# max32572 register map
Vendor: Maxim-Integrated; Series: ARMCM4; File version: 1.0
CPU: CM4 r2p1, little endian, MPU, FPU, 3 interrupt priority bits
Registers are 32-bit, read-write, reset 0x0 unless marked. A register's access mark holds for its fields unless they carry their own. Offsets are from the block's base; [hi:lo] are bit positions.

## RTC — Real Time Clock and Alarm.
Base 0x40006000
0x00 SEC reset not defined — RTC Second Counter. This register contains the 32-bit second counter.
  [31:0] SEC — Seconds Counter.
0x04 SSEC reset not defined — RTC Sub-second Counter. This counter increments at 256Hz. RTC_SEC is incremented when this register rolls over from 0xFF to 0x00.
  [11:0] SSEC — Sub-Seconds Counter (12-bit).
0x08 TODA reset not defined — Time-of-day Alarm.
  [19:0] TOD_ALARM
0x0C SSECA reset not defined — RTC sub-second alarm. This register contains the reload value for the sub-second alarm.
  [31:0] SSEC_ALARM — This register contains the reload value for the sub-second alarm.
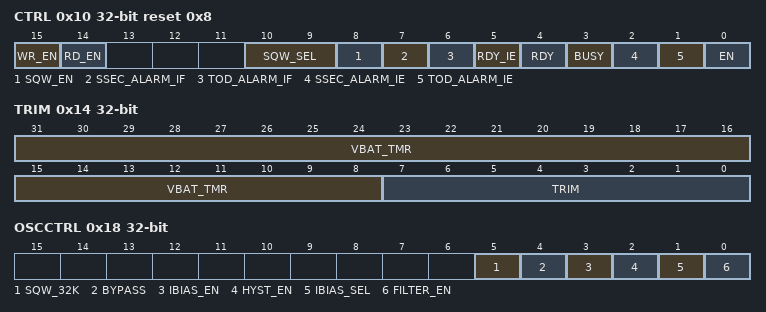
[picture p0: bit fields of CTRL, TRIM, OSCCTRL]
0x10 CTRL reset 0x8 (reset mask 0xFFFFFF38) — RTC Control Register.
  [15] WR_EN — Write Enable. This register bit serves as a protection mechanism against unintentional writes to critical RTC bits.
    0=Ignored; 1=Allowed
  [14] RD_EN — Asynchronous Counter Read Enable.
    0=Synchronous; 1=Asynchronous
  [10:9] SQW_SEL — Frequency Output Selection. When SQE=1, these bits specify the output frequency on the SQW pin.
    0=freq1Hz (1 Hz (Compensated).); 1=freq512Hz (512 Hz (Compensated).); 2=freq4KHz (4 KHz.); 3=clkDiv8 (RTC Input Clock / 8.)
  [8] SQW_EN — Square Wave Output Enable.
    0=dis (Disable.); 1=en (Enable.)
  [7] SSEC_ALARM_IF ro — Sub-second Alarm Interrupt Flag. This alarm is qualified as wake-up source to the processor.
    0=inactive (Not active.); 1=pending (Active.)
  [6] TOD_ALARM_IF ro — Time-of-Day Alarm Interrupt Flag. This alarm is qualified as wake-up source to the processor.
    0=inactive (Not active.); 1=pending (Active.)
  [5] RDY_IE — RTC Ready Interrupt Enable.
    0=dis (Disable.); 1=en (Enable.)
  [4] RDY — RTC Ready. This bit is set to 1 by hardware when the RTC count registers update. It can be cleared to 0 by software at any time. It will also be cleared to 0 by hardware just prior to an update of the RTC count register.
    0=busy (Register has not updated.); 1=ready
  [3] BUSY ro — RTC Busy. This bit is set to 1 by hardware when changes to RTC registers required a synchronized version of the register to be in place. This bit is automatically cleared by hardware.
    0=idle; 1=busy
  [2] SSEC_ALARM_IE — Alarm Sub-second Interrupt Enable. Change to this bit is effective only after BUSY is cleared from 1 to 0.
    0=dis (Disable.); 1=en (Enable.)
  [1] TOD_ALARM_IE — Alarm Time-of-Day Interrupt Enable. Change to this bit is effective only after BUSY is cleared from 1 to 0.
    0=dis (Disable.); 1=en (Enable.)
  [0] EN — Real Time Clock Enable. This bit enables the Real Time Clock. This bit can only be written when WE=1 and BUSY =0. Change to this bit is effective only after BUSY is cleared from 1 to 0.
    0=dis (Disable.); 1=en (Enable.)
0x14 TRIM reset not defined — RTC Trim Register.
  [31:8] VBAT_TMR — VBAT Timer Value. When RTC is running off of VBAT, this field is incremented every 32 seconds.
  [7:0] TRIM — RTC Trim. This register contains the 2's complement value that specifies the trim resolution. Each increment or decrement of the bit adds or subtracts 1ppm at each 4KHz clock value, with a maximum correction of +/- 127ppm.
0x18 OSCCTRL reset not defined — RTC Oscillator Control Register.
  [5] SQW_32K — RTC 32kHz Square Wave Output
    0=dis (Disable.); 1=en (Enable.)
  [4] BYPASS — RTC Crystal Bypass
    0=dis (Disable.); 1=en (Enable.)
  [3] IBIAS_EN — RTC IBIAS Enable.
  [2] HYST_EN — RTC Hysteresis Enable.
  [1] IBIAS_SEL — IBIAS Select.
    0=2x; 1=4x
  [0] FILTER_EN — Enable Filter.

## SIR — System Initialization Registers.
Base 0x40000400
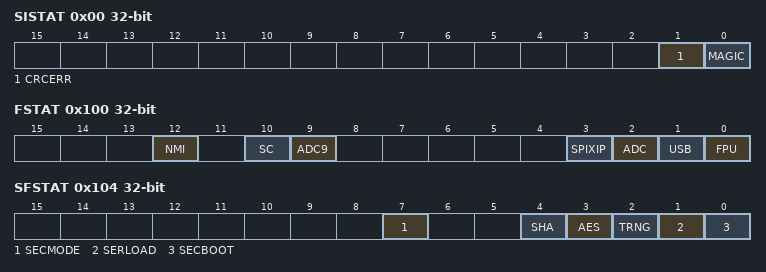
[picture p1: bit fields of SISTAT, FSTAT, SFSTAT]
0x00 SISTAT ro — System Initialization Status Register.
  [1] CRCERR — CRC Error Status. This bit is set by the system initialization block following power-up.
    on read: 0=noError (No CRC errors occurred during the read of the OTP memory block.); 1=error (A CRC error occurred while reading the OTP. The address of the failure location in the OTP memory is stored in the ERRADDR register.)
  [0] MAGIC — Magic Word Validation. This bit is set by the system initialization block following power-up.
    on read: 0=magicNotSet (Magic word was not set (OTP has not been initialized properly).); 1=magicSet (Magic word was set (OTP contains valid settings).)
0x04 SIADDR ro — Read-only field set by the SIB block if a CRC error occurs during the read of the OTP memory. Contains the failing address in OTP memory (when CRCERR equals 1).
  [31:0] ERRADDR
0x100 FSTAT ro — funcstat register.
  [all] fields
    0=no; 1=yes
  [12] NMI — NMI function.
  [10] SC — SC function.
  [9] ADC9 — ADC9 function.
  [3] SPIXIP — SPIXIPffunction.
  [2] ADC — 10-bit Sigma Delta ADC.
  [1] USB — USB Device.
  [0] FPU — FPU Function.
0x104 SFSTAT ro — Security Function
  [all] fields
    0=no; 1=yes
  [7] SECMODE — Security Mode Disable.
  [4] SHA — SHA function.
  [3] AES — AES function.
  [2] TRNG — TRNG function.
  [1] SERLOAD — Serial Load Disable function.
  [0] SECBOOT — Secure Boot Disable.
